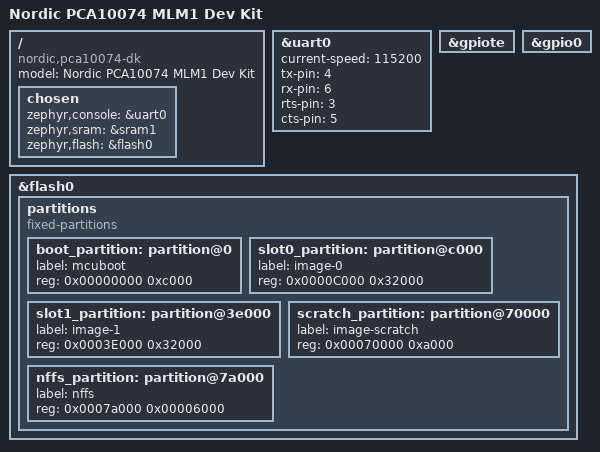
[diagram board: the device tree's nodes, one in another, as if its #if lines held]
/*
 * Copyright (c) 2017 Linaro Limited
 * Copyright (c) 2018 Nordic Semiconductor ASA
 *
 * SPDX-License-Identifier: Apache-2.0
 */

/dts-v1/;
#include <nordic/nrf9120_mlm1_xxaa.dtsi>

/ {
	model = "Nordic PCA10074 MLM1 Dev Kit";
	compatible = "nordic,pca10074-dk", "nordic,nrf9120-xxaa";

	chosen {
		zephyr,console = &uart0;
		zephyr,sram = &sram1;
		zephyr,flash = &flash0;
	};
};

&uart0 {
	current-speed = <115200>;
	status = "ok";
	tx-pin = <4>;
	rx-pin = <6>;
	rts-pin = <3>;
	cts-pin = <5>;

};

&gpiote {
	status = "ok";
};

&gpio0 {
	status = "ok";
};

&flash0 {
	/*
	 * For more information, see:
	 * http://docs.zephyrproject.org/devices/dts/flash_partitions.html
	 */
	partitions {
		compatible = "fixed-partitions";
		#address-cells = <1>;
		#size-cells = <1>;

		boot_partition: partition@0 {
			label = "mcuboot";
			reg = <0x00000000 0xc000>;
		};
		slot0_partition: partition@c000 {
			label = "image-0";
			reg = <0x0000C000 0x32000>;
		};
		slot1_partition: partition@3e000 {
			label = "image-1";
			reg = <0x0003E000 0x32000>;
		};
		scratch_partition: partition@70000 {
			label = "image-scratch";
			reg = <0x00070000 0xa000>;
		};

#if defined(CONFIG_FILE_SYSTEM_NFFS)
		nffs_partition: partition@7a000 {
			label = "nffs";
			reg = <0x0007a000 0x00006000>;
		};
#endif
	};
};
